# HDSC_HC32F460KEUA register map
Vendor: HDSC Co.,Ltd.; Series: ARMCM4; File version: 1.0
CPU: CM4 r0p1, little endian, MPU, FPU, 4 interrupt priority bits
Registers are 32-bit, read-write, reset 0x0 unless marked. A register's access mark holds for its fields unless they carry their own. Offsets are from the block's base; [hi:lo] are bit positions; {n}, {i} and the like mark numbered series; 'fields as' and 'values as' point back to an identical list.

## INTC
Base 0x40051000
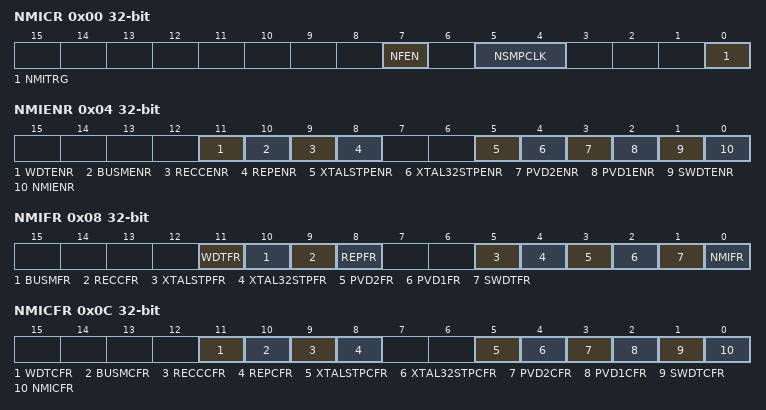
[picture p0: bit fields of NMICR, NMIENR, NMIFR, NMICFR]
0x00 NMICR
  [7] NFEN, [5:4] NSMPCLK, [0] NMITRG
0x04 NMIENR
  [11] WDTENR, [10] BUSMENR, [9] RECCENR, [8] REPENR, [5] XTALSTPENR, [4] XTAL32STPENR, [3] PVD2ENR, [2] PVD1ENR, [1] SWDTENR, [0] NMIENR
0x08 NMIFR
  [11] WDTFR, [10] BUSMFR, [9] RECCFR, [8] REPFR, [5] XTALSTPFR, [4] XTAL32STPFR, [3] PVD2FR, [2] PVD1FR, [1] SWDTFR, [0] NMIFR
0x0C NMICFR
  [11] WDTCFR, [10] BUSMCFR, [9] RECCCFR, [8] REPCFR, [5] XTALSTPCFR, [4] XTAL32STPCFR, [3] PVD2CFR, [2] PVD1CFR, [1] SWDTCFR, [0] NMICFR
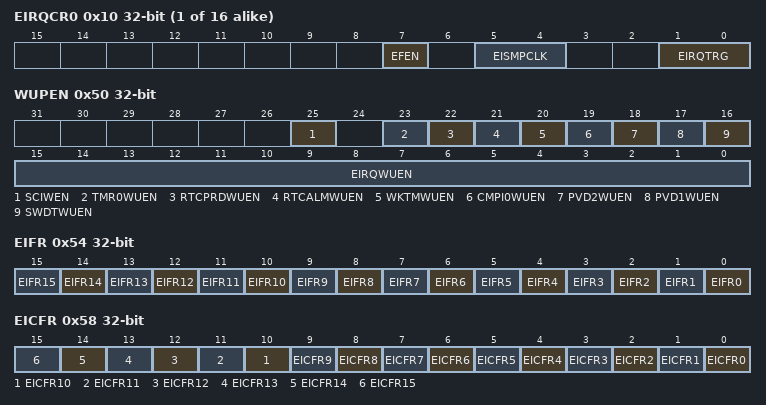
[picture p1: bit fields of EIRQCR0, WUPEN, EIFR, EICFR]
{0x10+4i} EIRQCR{i} (i=0..15)
  [7] EFEN, [5:4] EISMPCLK, [1:0] EIRQTRG
0x50 WUPEN
  [25] SCIWEN, [23] TMR0WUEN, [22] RTCPRDWUEN, [21] RTCALMWUEN, [20] WKTMWUEN, [19] CMPI0WUEN, [18] PVD2WUEN, [17] PVD1WUEN, [16] SWDTWUEN, [15:0] EIRQWUEN
0x54 EIFR
  [n] EIFR{n} (n=0..15)
0x58 EICFR
  [n] EICFR{n} (n=0..15)
{0x5C+4i} SEL{i} reset 0x1FF (i=0..127)
  [8:0] INTSEL
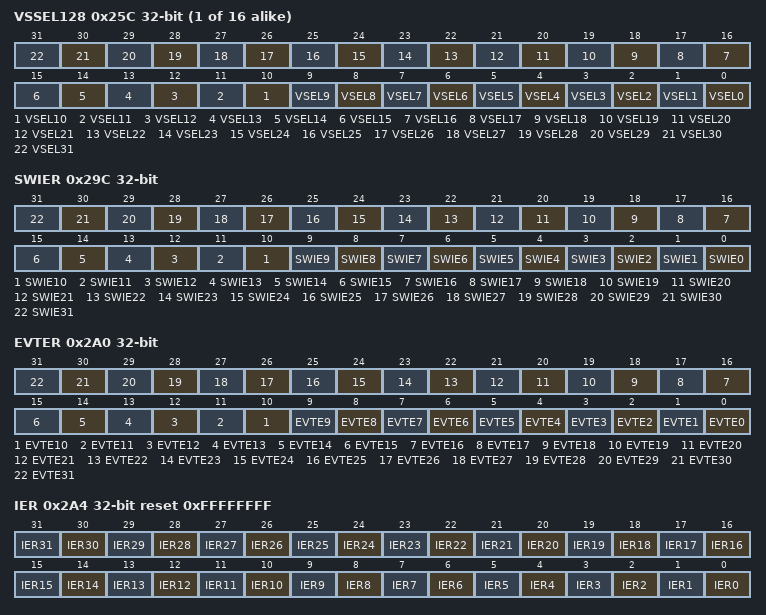
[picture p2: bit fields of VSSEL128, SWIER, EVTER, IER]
{0x5C+4i} VSSEL{i} (i=128..143)
  [n] VSEL{n} (n=0..31)
0x29C SWIER
  [n] SWIE{n} (n=0..31)
0x2A0 EVTER
  [n] EVTE{n} (n=0..31)
0x2A4 IER reset 0xFFFFFFFF
  [n] IER{n} (n=0..31)

## KEYSCAN
Base 0x40050C00
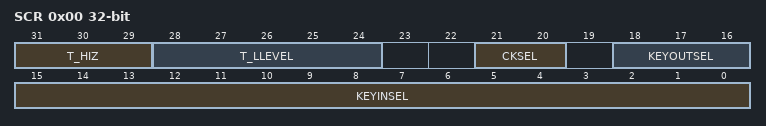
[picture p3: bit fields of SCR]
0x00 SCR
  [31:29] T_HIZ, [28:24] T_LLEVEL, [21:20] CKSEL, [18:16] KEYOUTSEL, [15:0] KEYINSEL
0x04 SER
  [0] SEN
0x08 SSR (reset mask 0x3)
  [2:0] INDEX

## MPU
Base 0x40050000
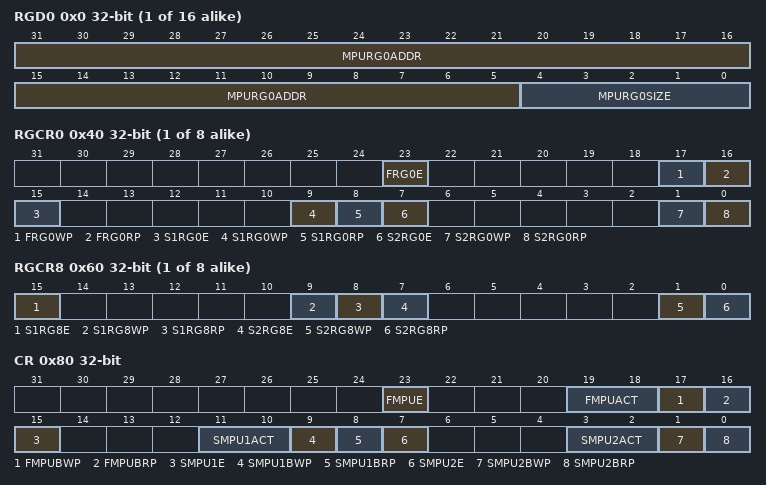
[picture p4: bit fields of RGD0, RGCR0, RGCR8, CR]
{0x0+4i} RGD{i} (i=0..15)
  [31:5] MPURG{i}ADDR, [4:0] MPURG{i}SIZE
{0x40+4i} RGCR{i} (i=0..7)
  [23] FRG{i}E, [17] FRG{i}WP, [16] FRG{i}RP, [15] S1RG{i}E, [9] S1RG{i}WP, [8] S1RG{i}RP, [7] S2RG{i}E, [1] S2RG{i}WP, [0] S2RG{i}RP
{0x40+4i} RGCR{i} (i=8..15)
  [15] S1RG{i}E, [9] S1RG{i}WP, [8] S1RG{i}RP, [7] S2RG{i}E, [1] S2RG{i}WP, [0] S2RG{i}RP
0x80 CR
  [23] FMPUE, [19:18] FMPUACT, [17] FMPUBWP, [16] FMPUBRP, [15] SMPU1E, [11:10] SMPU1ACT, [9] SMPU1BWP, [8] SMPU1BRP, [7] SMPU2E, [3:2] SMPU2ACT, [1] SMPU2BWP, [0] SMPU2BRP
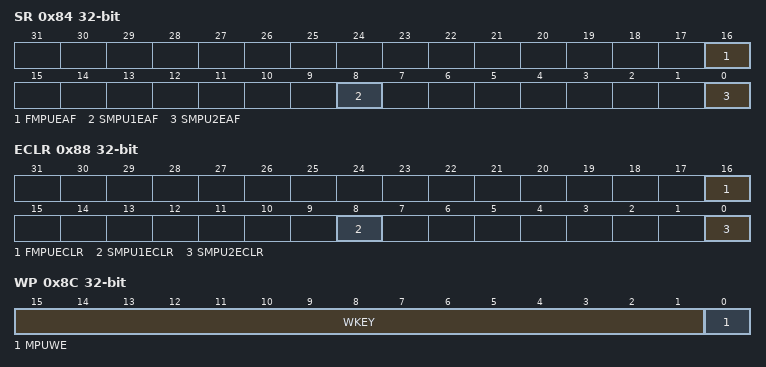
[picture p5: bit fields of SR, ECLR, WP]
0x84 SR ro
  [16] FMPUEAF, [8] SMPU1EAF, [0] SMPU2EAF
0x88 ECLR wo
  [16] FMPUECLR, [8] SMPU1ECLR, [0] SMPU2ECLR
0x8C WP
  [15:1] WKEY wo, [0] MPUWE

## MSTP
Base 0x40048000
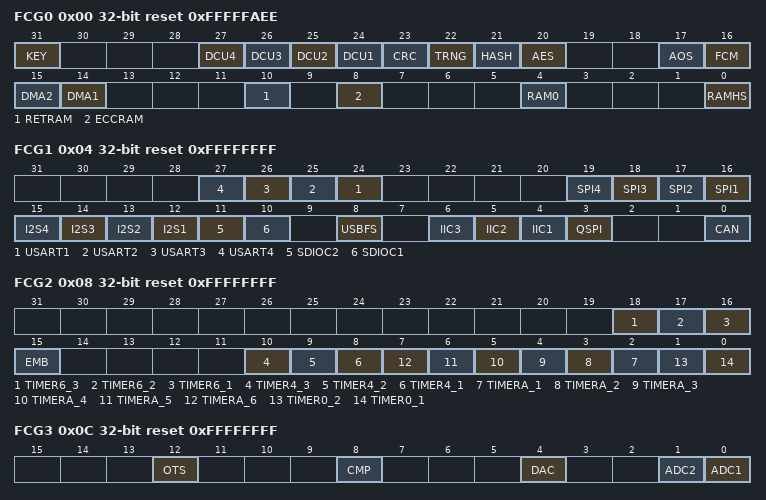
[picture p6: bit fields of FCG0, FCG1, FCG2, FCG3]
0x00 FCG0 reset 0xFFFFFAEE
  [31] KEY, [n+23] DCU{n} (n=1..4), [23] CRC, [22] TRNG, [21] HASH, [20] AES, [17] AOS, [16] FCM, [15] DMA2, [14] DMA1, [10] RETRAM, [8] ECCRAM, [4] RAM0, [0] RAMHS
0x04 FCG1 reset 0xFFFFFFFF
  [n+23] USART{n} (n=1..4), [n+15] SPI{n} (n=1..4), [n+11] I2S{n} (n=1..4), [11] SDIOC2, [10] SDIOC1, [8] USBFS, [6] IIC3, [5] IIC2, [4] IIC1, [3] QSPI, [0] CAN
0x08 FCG2 reset 0xFFFFFFFF
  [18] TIMER6_3, [17] TIMER6_2, [16] TIMER6_1, [15] EMB, [10] TIMER4_3, [9] TIMER4_2, [8] TIMER4_1, [n+1] TIMERA_{n} (n=1..6), [1] TIMER0_2, [0] TIMER0_1
0x0C FCG3 reset 0xFFFFFFFF
  [12] OTS, [8] CMP, [4] DAC, [1] ADC2, [0] ADC1
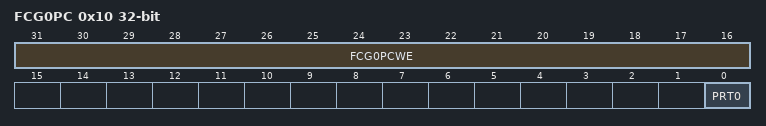
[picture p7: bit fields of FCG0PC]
0x10 FCG0PC
  [31:16] FCG0PCWE wo, [0] PRT0

## OTS
Base 0x4004A400
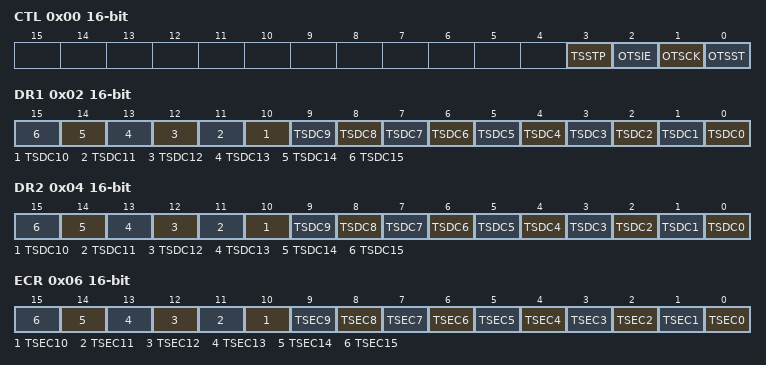
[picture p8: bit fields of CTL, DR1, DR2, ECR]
0x00 CTL 16-bit
  [3] TSSTP, [2] OTSIE, [1] OTSCK, [0] OTSST
0x02 DR1 16-bit
  [n] TSDC{n} (n=0..15)
0x04 DR2 16-bit
  [n] TSDC{n} (n=0..15)
0x06 ECR 16-bit
  [n] TSEC{n} (n=0..15)
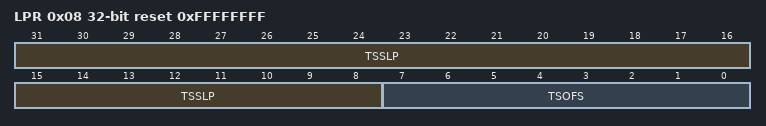
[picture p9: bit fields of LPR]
0x08 LPR ro reset 0xFFFFFFFF
  [31:8] TSSLP, [7:0] TSOFS

## PERIC
Base 0x40055400
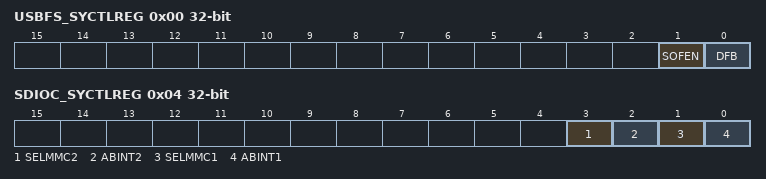
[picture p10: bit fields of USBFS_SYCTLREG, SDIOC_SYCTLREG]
0x00 USBFS_SYCTLREG
  [1] SOFEN, [0] DFB
0x04 SDIOC_SYCTLREG
  [3] SELMMC2, [2] ABINT2, [1] SELMMC1, [0] ABINT1

## PORT
Base 0x40053800
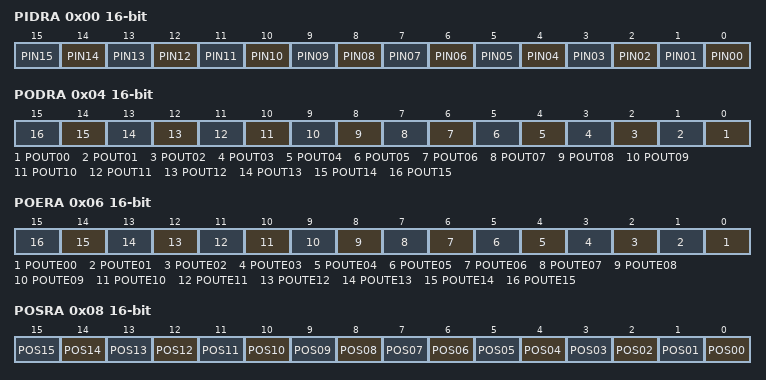
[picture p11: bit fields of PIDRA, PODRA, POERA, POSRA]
0x00 PIDRA 16-bit ro
  [n] PIN{n:02} (n=0..15)
0x04 PODRA 16-bit
  [n] POUT{n:02} (n=0..15)
0x06 POERA 16-bit
  [n] POUTE{n:02} (n=0..15)
0x08 POSRA 16-bit wo
  [n] POS{n:02} (n=0..15)
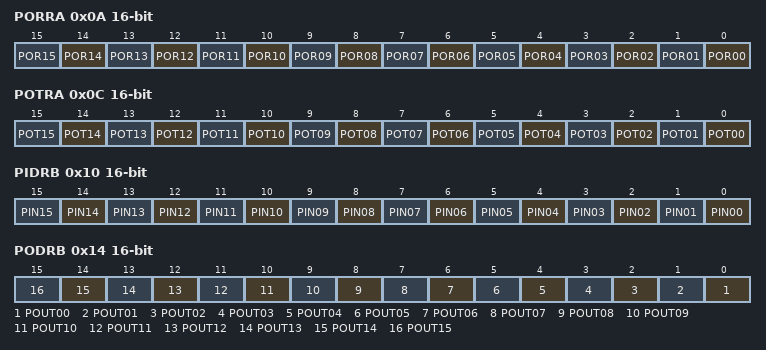
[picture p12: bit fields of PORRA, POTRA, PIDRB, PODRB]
0x0A PORRA 16-bit wo
  [n] POR{n:02} (n=0..15)
0x0C POTRA 16-bit wo
  [n] POT{n:02} (n=0..15)
0x10 PIDRB 16-bit ro
  [n] PIN{n:02} (n=0..15)
0x14 PODRB 16-bit
  [n] POUT{n:02} (n=0..15)
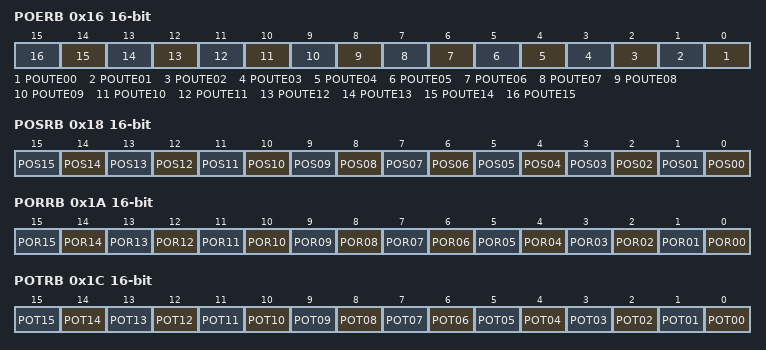
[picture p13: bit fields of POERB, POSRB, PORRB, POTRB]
0x16 POERB 16-bit
  [n] POUTE{n:02} (n=0..15)
0x18 POSRB 16-bit wo
  [n] POS{n:02} (n=0..15)
0x1A PORRB 16-bit wo
  [n] POR{n:02} (n=0..15)
0x1C POTRB 16-bit wo
  [n] POT{n:02} (n=0..15)
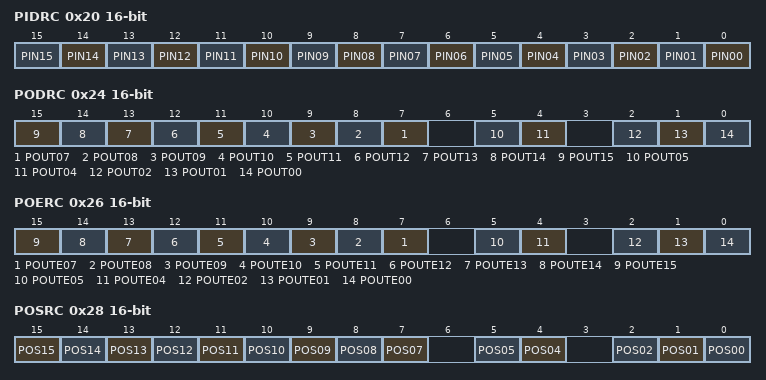
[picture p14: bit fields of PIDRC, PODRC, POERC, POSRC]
0x20 PIDRC 16-bit ro
  [n] PIN{n:02} (n=0..15)
0x24 PODRC 16-bit
  [n] POUT{n:02} (n=7..15), [5] POUT05, [4] POUT04, [2] POUT02, [1] POUT01, [0] POUT00
0x26 POERC 16-bit
  [n] POUTE{n:02} (n=7..15), [5] POUTE05, [4] POUTE04, [2] POUTE02, [1] POUTE01, [0] POUTE00
0x28 POSRC 16-bit wo
  [n] POS{n:02} (n=7..15), [5] POS05, [4] POS04, [2] POS02, [1] POS01, [0] POS00
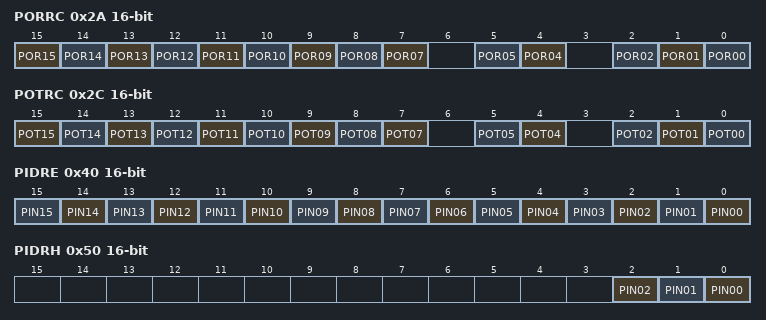
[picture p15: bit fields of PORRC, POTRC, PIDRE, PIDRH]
0x2A PORRC 16-bit wo
  [n] POR{n:02} (n=7..15), [5] POR05, [4] POR04, [2] POR02, [1] POR01, [0] POR00
0x2C POTRC 16-bit wo
  [n] POT{n:02} (n=7..15), [5] POT05, [4] POT04, [2] POT02, [1] POT01, [0] POT00
0x40 PIDRE 16-bit ro
  [n] PIN{n:02} (n=0..15)
0x44 PODRE 16-bit
  [15] POUT15
0x46 POERE 16-bit
  [15] POUTE15
0x48 POSRE 16-bit wo
  [15] POS15
0x4A PORRE 16-bit wo
  [15] POR15
0x4C POTRE 16-bit wo
  [15] POT15
0x50 PIDRH 16-bit ro
  [2] PIN02, [1] PIN01, [0] PIN00
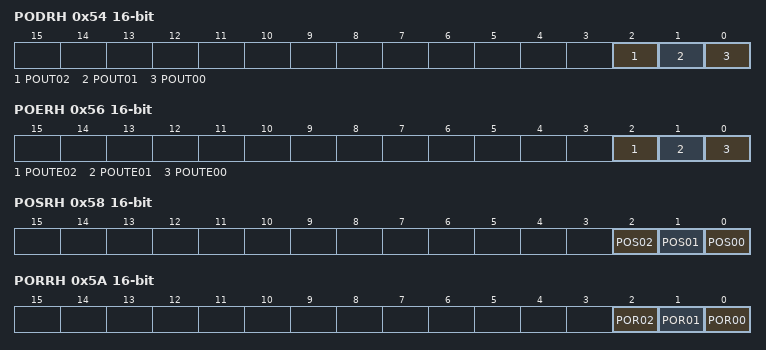
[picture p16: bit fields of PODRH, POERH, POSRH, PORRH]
0x54 PODRH 16-bit
  [2] POUT02, [1] POUT01, [0] POUT00
0x56 POERH 16-bit
  [2] POUTE02, [1] POUTE01, [0] POUTE00
0x58 POSRH 16-bit wo
  [2] POS02, [1] POS01, [0] POS00
0x5A PORRH 16-bit wo
  [2] POR02, [1] POR01, [0] POR00
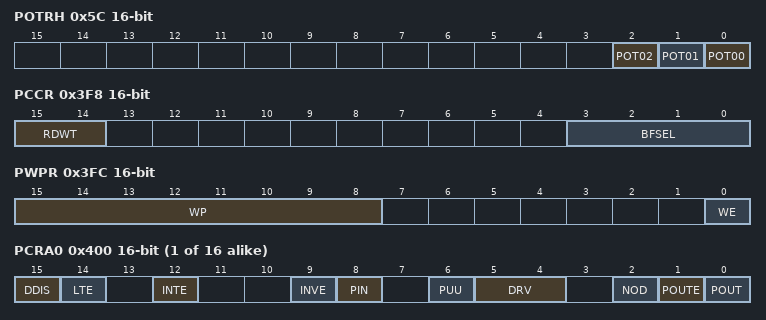
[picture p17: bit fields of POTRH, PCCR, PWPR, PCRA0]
0x5C POTRH 16-bit wo
  [2] POT02, [1] POT01, [0] POT00
0x3F4 PSPCR 16-bit
  [4:0] SPFE
0x3F8 PCCR 16-bit
  [15:14] RDWT, [3:0] BFSEL
0x3FA PINAER 16-bit
  [5:0] PINAE
0x3FC PWPR 16-bit
  [15:8] WP wo, [0] WE
{0x400+4i} PCRA{i} 16-bit (i=0..15)
  [15] DDIS, [14] LTE, [12] INTE, [9] INVE, [8] PIN ro, [6] PUU, [5:4] DRV, [2] NOD, [1] POUTE, [0] POUT
{0x402+4i} PFSRA{i} 16-bit (i=0..15)
  [8] BFE, [5:0] FSEL
{0x440+4i} PCRB{i} 16-bit (i=0..15)
  fields as PCRA0
{0x442+4i} PFSRB{i} 16-bit (i=0..15)
  [8] BFE, [5:0] FSEL
{0x480+4i} PCRC{i} 16-bit (i=0..2)
  fields as PCRA0
{0x482+4i} PFSRC{i} 16-bit (i=0..2)
  [8] BFE, [5:0] FSEL
0x490 PCRC4 16-bit
  fields as PCRA0
0x492 PFSRC4 16-bit
  [8] BFE, [5:0] FSEL
0x494 PCRC5 16-bit
  fields as PCRA0
0x496 PFSRC5 16-bit
  [8] BFE, [5:0] FSEL
{0x480+4i} PCRC{i} 16-bit (i=7..15)
  fields as PCRA0
{0x482+4i} PFSRC{i} 16-bit (i=7..15)
  [8] BFE, [5:0] FSEL
0x53C PCRE15 16-bit
  fields as PCRA0
0x53E PFSRE15 16-bit
  [8] BFE, [5:0] FSEL
{0x540+4i} PCRH{i} 16-bit (i=0..2)
  fields as PCRA0
{0x542+4i} PFSRH{i} 16-bit (i=0..2)
  [8] BFE, [5:0] FSEL
